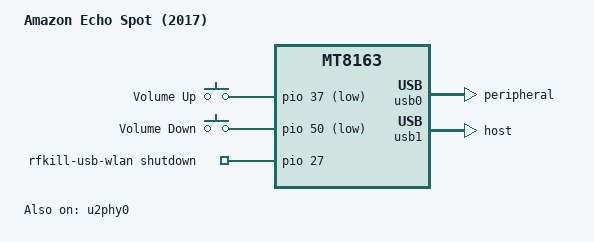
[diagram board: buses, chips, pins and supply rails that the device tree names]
// SPDX-License-Identifier: GPL-2.0-only OR MIT
/*
 * Copyright (c) 2025-2026 Ben Grisdale <bengris32@protonmail.ch>
 */

/dts-v1/;
#include <dt-bindings/gpio/gpio.h>
#include <dt-bindings/input/input.h>

#include "mt8163-amazon-common.dtsi"

/ {
	model = "Amazon Echo Spot (2017)";
	compatible = "amazon,rook", "mediatek,mt8163";
	chassis-type = "embedded";

	gpio-keys {
		compatible = "gpio-keys";
		pinctrl-names = "default";
		pinctrl-0 = <&gpio_keys_pins>;

		key-volume-up {
			label = "Volume Up";
			linux,code = <KEY_VOLUMEUP>;
			gpios = <&pio 37 GPIO_ACTIVE_LOW>;
			debounce-interval = <20>;
		};

		key-volume-down {
			label = "Volume Down";
			linux,code = <KEY_VOLUMEDOWN>;
			gpios = <&pio 50 GPIO_ACTIVE_LOW>;
			debounce-interval = <20>;
		};
	};

	rfkill {
		compatible = "rfkill-gpio";
		pinctrl-names = "default";
		pinctrl-0 = <&wifi_pwr_pins>;
		label = "rfkill-usb-wlan";
		radio-type = "wlan";
		shutdown-gpios = <&pio 27 GPIO_ACTIVE_HIGH>;
	};
};

&mt6323_vusb_reg {
	regulator-always-on;
};

&u2phy0 {
	status = "okay";
};

&usb0 {
	/* No 5V supply for OTG support. */
	dr_mode = "peripheral";
	status = "okay";
};

&usb1 {
	/* For internal Wi-Fi adapter */
	dr_mode = "host";
	status = "okay";
};

&pio {
	gpio_keys_pins: gpio-keys-pins {
		pins {
			pinmux = <MT8163_PIN_37_KPCOL1__FUNC_GPIO37>,
				 <MT8163_PIN_50_EINT18__FUNC_GPIO50>;
			bias-pull-up;
			input-enable;
		};
	};

	wifi_pwr_pins: wifi-pwr-pins {
		pins {
			pinmux = <MT8163_PIN_27_EINT5__FUNC_GPIO27>;
		};
	};
};
